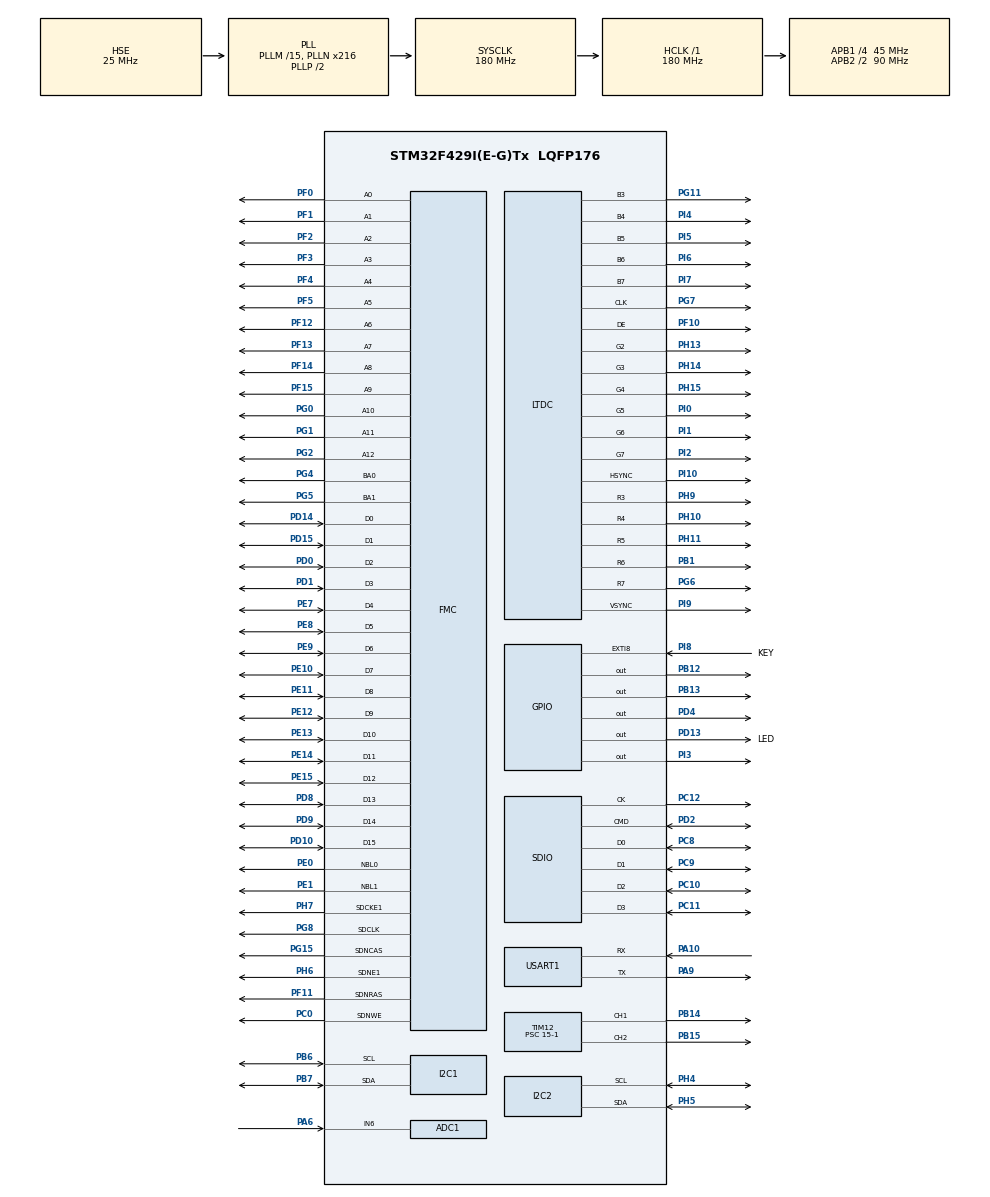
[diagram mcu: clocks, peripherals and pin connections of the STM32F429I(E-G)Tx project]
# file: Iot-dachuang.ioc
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ADC1.Channel-1\#ChannelRegularConversion=ADC_CHANNEL_6
ADC1.DMAContinuousRequests=ENABLE
ADC1.ExternalTrigConv=ADC_EXTERNALTRIGCONV_T3_TRGO
ADC1.NbrOfConversionFlag=1
ADC1.Rank-1\#ChannelRegularConversion=1
ADC1.SamplingTime-1\#ChannelRegularConversion=ADC_SAMPLETIME_3CYCLES
ADC1.master=1
DMA2D.ColorMode=DMA2D_OUTPUT_RGB565
DMA2D.Mode=DMA2D_M2M
Dma.ADC1.2.Direction=DMA_PERIPH_TO_MEMORY
Dma.ADC1.2.FIFOMode=DMA_FIFOMODE_DISABLE
Dma.ADC1.2.Instance=DMA2_Stream0
Dma.ADC1.2.MemDataAlignment=DMA_MDATAALIGN_HALFWORD
Dma.ADC1.2.MemInc=DMA_MINC_ENABLE
Dma.ADC1.2.Mode=DMA_NORMAL
Dma.ADC1.2.PeriphDataAlignment=DMA_PDATAALIGN_HALFWORD
Dma.ADC1.2.PeriphInc=DMA_PINC_DISABLE
Dma.ADC1.2.Priority=DMA_PRIORITY_LOW
Dma.Request0=SDIO_RX
Dma.Request1=SDIO_TX
Dma.Request2=ADC1
Dma.SDIO_RX.0.Direction=DMA_PERIPH_TO_MEMORY
Dma.SDIO_RX.0.FIFOMode=DMA_FIFOMODE_ENABLE
Dma.SDIO_RX.0.FIFOThreshold=DMA_FIFO_THRESHOLD_FULL
Dma.SDIO_RX.0.Instance=DMA2_Stream3
Dma.SDIO_RX.0.MemBurst=DMA_MBURST_INC4
Dma.SDIO_RX.0.MemDataAlignment=DMA_MDATAALIGN_WORD
Dma.SDIO_RX.0.MemInc=DMA_MINC_ENABLE
Dma.SDIO_RX.0.Mode=DMA_PFCTRL
Dma.SDIO_RX.0.PeriphBurst=DMA_PBURST_INC4
Dma.SDIO_RX.0.PeriphDataAlignment=DMA_PDATAALIGN_WORD
Dma.SDIO_RX.0.PeriphInc=DMA_PINC_DISABLE
Dma.SDIO_RX.0.Priority=DMA_PRIORITY_LOW
Dma.SDIO_TX.1.Direction=DMA_MEMORY_TO_PERIPH
Dma.SDIO_TX.1.FIFOMode=DMA_FIFOMODE_ENABLE
Dma.SDIO_TX.1.FIFOThreshold=DMA_FIFO_THRESHOLD_FULL
Dma.SDIO_TX.1.Instance=DMA2_Stream6
Dma.SDIO_TX.1.MemBurst=DMA_MBURST_INC4
Dma.SDIO_TX.1.MemDataAlignment=DMA_MDATAALIGN_WORD
Dma.SDIO_TX.1.MemInc=DMA_MINC_ENABLE
Dma.SDIO_TX.1.Mode=DMA_PFCTRL
Dma.SDIO_TX.1.PeriphBurst=DMA_PBURST_INC4
Dma.SDIO_TX.1.PeriphDataAlignment=DMA_PDATAALIGN_WORD
Dma.SDIO_TX.1.PeriphInc=DMA_PINC_DISABLE
Dma.SDIO_TX.1.Priority=DMA_PRIORITY_LOW
FATFS._CODE_PAGE=936
FATFS._USE_LFN=2
FATFS._USE_MUTEX=1
FMC.CASLatency2=FMC_SDRAM_CAS_LATENCY_3
FMC.ColumnBitsNumber2=FMC_SDRAM_COLUMN_BITS_NUM_9
FMC.ExitSelfRefreshDelay2=7
FMC.LoadToActiveDelay2=2
FMC.RCDDelay2=2
FMC.RPDelay2=2
FMC.ReadBurst2=FMC_SDRAM_RBURST_ENABLE
FMC.ReadPipeDelay2=FMC_SDRAM_RPIPE_DELAY_1
FMC.RowCycleDelay2=7
FMC.SDClockPeriod2=FMC_SDRAM_CLOCK_PERIOD_2
FMC.SelfRefreshTime2=4
FMC.WriteRecoveryTime2=3
FREERTOS.Tasks01=defaultTask,0,512,StartDefaultTask,Default,NULL,Dynamic,NULL,NULL;GUI,-3,512,GUItask,Default,NULL,Dynamic,NULL,NULL;Measure,-3,512,Measuretask,Default,NULL,Dynamic,NULL,NULL;Control,-3,128,Contorl,Default,NULL,Dynamic,NULL,NULL
FREERTOS.configENABLE_FPU=1
FREERTOS.configUSE_NEWLIB_REENTRANT=1
LTDC.ActiveH=272
LTDC.ActiveW=480
LTDC.Alpha_L0=255
LTDC.BlendingFactor1_L0=LTDC_BLENDING_FACTOR1_CA
LTDC.BlendingFactor1_L1=LTDC_BLENDING_FACTOR1_PAxCA
LTDC.BlendingFactor2_L0=LTDC_BLENDING_FACTOR2_CA
LTDC.BlendingFactor2_L1=LTDC_BLENDING_FACTOR2_PAxCA
LTDC.FBStartAdress_L0=0xD0000000
LTDC.FBStartAdress_L1=0xDD000000
LTDC.HBP=43
LTDC.HFP=8
LTDC.HSync=1
LTDC.ImageHeight_L0=272
LTDC.ImageHeight_L1=272
LTDC.ImageWidth_L0=480
LTDC.ImageWidth_L1=480
LTDC.Layers=0
LTDC.PixelFormat_L0=LTDC_PIXEL_FORMAT_RGB565
LTDC.VBP=12
LTDC.VFP=8
LTDC.VSync=1
LTDC.WindowX1_L0=480
LTDC.WindowX1_L1=480
LTDC.WindowY1_L0=272
LTDC.WindowY1_L1=272
Mcu.Family=STM32F4
Mcu.Name=STM32F429I(E-G)Tx
Mcu.Package=LQFP176
NVIC.DMA2D_IRQn=true\:5\:0\:false\:false\:true\:true\:true\:true\:true
NVIC.DMA2_Stream3_IRQn=true\:5\:0\:false\:false\:true\:true\:true\:true\:true
NVIC.DMA2_Stream6_IRQn=true\:5\:0\:false\:false\:true\:true\:true\:true\:true
NVIC.EXTI9_5_IRQn=true\:5\:0\:false\:false\:true\:true\:true\:true\:true
NVIC.LTDC_IRQn=true\:5\:0\:false\:false\:true\:true\:true\:true\:true
NVIC.PriorityGroup=NVIC_PRIORITYGROUP_4
NVIC.SDIO_IRQn=true\:5\:0\:false\:false\:true\:true\:true\:true\:true
NVIC.TIM1_UP_TIM10_IRQn=true\:5\:0\:false\:false\:true\:false\:false\:true\:true
NVIC.TimeBase=TIM1_UP_TIM10_IRQn
NVIC.TimeBaseIP=TIM1
NVIC.USART1_IRQn=true\:5\:0\:false\:false\:true\:true\:true\:true\:true
PA10.Mode=Asynchronous
PA10.Signal=USART1_RX
PA13.Mode=Serial_Wire
PA13.Signal=SYS_JTMS-SWDIO
PA14.Mode=Serial_Wire
PA14.Signal=SYS_JTCK-SWCLK
PA6.Signal=ADCx_IN6
PA9.Mode=Asynchronous
PA9.Signal=USART1_TX
PB1.GPIO_PuPd=GPIO_NOPULL
PB1.GPIO_Speed=GPIO_SPEED_FREQ_LOW
PB1.Mode=RGB565
PB1.Signal=LTDC_R6
PB12.GPIO_PuPd=GPIO_PULLUP
PB12.PinState=GPIO_PIN_SET
PB12.Signal=GPIO_Output
PB13.GPIO_PuPd=GPIO_PULLUP
PB13.PinState=GPIO_PIN_SET
PB13.Signal=GPIO_Output
PB14.GPIO_PuPd=GPIO_NOPULL
PB14.GPIO_Speed=GPIO_SPEED_FREQ_LOW
PB14.Signal=S_TIM12_CH1
PB15.Signal=S_TIM12_CH2
PB6.Mode=I2C
PB6.Signal=I2C1_SCL
PB7.Mode=I2C
PB7.Signal=I2C1_SDA
PC0.Signal=FMC_SDNWE
PC10.GPIO_PuPd=GPIO_PULLUP
PC10.Mode=SD_4_bits_Wide_bus
PC10.Signal=SDIO_D2
PC11.GPIO_PuPd=GPIO_PULLUP
PC11.Mode=SD_4_bits_Wide_bus
PC11.Signal=SDIO_D3
PC12.GPIO_PuPd=GPIO_PULLUP
PC12.Mode=SD_4_bits_Wide_bus
PC12.Signal=SDIO_CK
PC8.GPIO_PuPd=GPIO_PULLUP
PC8.Mode=SD_4_bits_Wide_bus
PC8.Signal=SDIO_D0
PC9.GPIO_PuPd=GPIO_PULLUP
PC9.Mode=SD_4_bits_Wide_bus
PC9.Signal=SDIO_D1
PD0.Signal=FMC_D2_DA2
PD1.Signal=FMC_D3_DA3
PD10.Signal=FMC_D15_DA15
PD13.GPIO_Label=LED
PD13.GPIO_PuPd=GPIO_PULLUP
PD13.PinState=GPIO_PIN_SET
PD13.Signal=GPIO_Output
PD14.Signal=FMC_D0_DA0
PD15.Signal=FMC_D1_DA1
PD2.GPIO_PuPd=GPIO_PULLUP
PD2.Mode=SD_4_bits_Wide_bus
PD2.Signal=SDIO_CMD
PD4.Signal=GPIO_Output
PD8.Signal=FMC_D13_DA13
PD9.Signal=FMC_D14_DA14
PE0.Signal=FMC_NBL0
PE1.Signal=FMC_NBL1
PE10.Signal=FMC_D7_DA7
PE11.Signal=FMC_D8_DA8
PE12.Signal=FMC_D9_DA9
PE13.Signal=FMC_D10_DA10
PE14.Signal=FMC_D11_DA11
PE15.Signal=FMC_D12_DA12
PE7.Signal=FMC_D4_DA4
PE8.Signal=FMC_D5_DA5
PE9.Signal=FMC_D6_DA6
PF0.Signal=FMC_A0
PF1.Signal=FMC_A1
PF10.GPIO_PuPd=GPIO_NOPULL
PF10.GPIO_Speed=GPIO_SPEED_FREQ_LOW
PF10.Mode=RGB565
PF10.Signal=LTDC_DE
PF11.Signal=FMC_SDNRAS
PF12.Signal=FMC_A6
PF13.Signal=FMC_A7
PF14.Signal=FMC_A8
PF15.Signal=FMC_A9
PF2.Signal=FMC_A2
PF3.Signal=FMC_A3
PF4.Signal=FMC_A4
PF5.Signal=FMC_A5
PG0.Signal=FMC_A10
PG1.Signal=FMC_A11
PG11.GPIO_PuPd=GPIO_NOPULL
PG11.GPIO_Speed=GPIO_SPEED_FREQ_LOW
PG11.Mode=RGB565
PG11.Signal=LTDC_B3
PG15.Signal=FMC_SDNCAS
PG2.Signal=FMC_A12
PG4.Signal=FMC_A14_BA0
PG5.Signal=FMC_A15_BA1
PG6.GPIO_PuPd=GPIO_NOPULL
PG6.GPIO_Speed=GPIO_SPEED_FREQ_LOW
PG6.Mode=RGB565
PG6.Signal=LTDC_R7
PG7.GPIO_PuPd=GPIO_NOPULL
PG7.GPIO_Speed=GPIO_SPEED_FREQ_LOW
PG7.Mode=RGB565
PG7.Signal=LTDC_CLK
PG8.Signal=FMC_SDCLK
PH0/OSC_IN.Mode=HSE-External-Oscillator
PH0/OSC_IN.Signal=RCC_OSC_IN
PH1/OSC_OUT.Mode=HSE-External-Oscillator
PH1/OSC_OUT.Signal=RCC_OSC_OUT
PH10.GPIO_PuPd=GPIO_NOPULL
PH10.GPIO_Speed=GPIO_SPEED_FREQ_LOW
PH10.Mode=RGB565
PH10.Signal=LTDC_R4
PH11.GPIO_PuPd=GPIO_NOPULL
PH11.GPIO_Speed=GPIO_SPEED_FREQ_LOW
PH11.Mode=RGB565
PH11.Signal=LTDC_R5
PH13.GPIO_PuPd=GPIO_NOPULL
PH13.GPIO_Speed=GPIO_SPEED_FREQ_LOW
PH13.Mode=RGB565
PH13.Signal=LTDC_G2
PH14.GPIO_PuPd=GPIO_NOPULL
PH14.GPIO_Speed=GPIO_SPEED_FREQ_LOW
PH14.Mode=RGB565
PH14.Signal=LTDC_G3
PH15.GPIO_PuPd=GPIO_NOPULL
PH15.GPIO_Speed=GPIO_SPEED_FREQ_LOW
PH15.Mode=RGB565
PH15.Signal=LTDC_G4
PH4.Mode=I2C
PH4.Signal=I2C2_SCL
PH5.Mode=I2C
PH5.Signal=I2C2_SDA
PH6.Mode=SdramChipSelect2_2
PH6.Signal=FMC_SDNE1
PH7.Mode=SdramChipSelect2_2
PH7.Signal=FMC_SDCKE1
PH9.GPIO_PuPd=GPIO_NOPULL
PH9.GPIO_Speed=GPIO_SPEED_FREQ_LOW
PH9.Mode=RGB565
PH9.Signal=LTDC_R3
PI0.GPIO_PuPd=GPIO_NOPULL
PI0.GPIO_Speed=GPIO_SPEED_FREQ_LOW
PI0.Mode=RGB565
PI0.Signal=LTDC_G5
PI1.GPIO_PuPd=GPIO_NOPULL
PI1.GPIO_Speed=GPIO_SPEED_FREQ_LOW
PI1.Mode=RGB565
PI1.Signal=LTDC_G6
PI10.GPIO_PuPd=GPIO_NOPULL
PI10.GPIO_Speed=GPIO_SPEED_FREQ_LOW
PI10.Mode=RGB565
PI10.Signal=LTDC_HSYNC
PI2.GPIO_PuPd=GPIO_NOPULL
PI2.GPIO_Speed=GPIO_SPEED_FREQ_LOW
PI2.Mode=RGB565
PI2.Signal=LTDC_G7
PI3.GPIO_PuPd=GPIO_NOPULL
PI3.PinState=GPIO_PIN_RESET
PI3.Signal=GPIO_Output
PI4.GPIO_PuPd=GPIO_NOPULL
PI4.GPIO_Speed=GPIO_SPEED_FREQ_LOW
PI4.Mode=RGB565
PI4.Signal=LTDC_B4
PI5.GPIO_PuPd=GPIO_NOPULL
PI5.GPIO_Speed=GPIO_SPEED_FREQ_LOW
PI5.Mode=RGB565
PI5.Signal=LTDC_B5
PI6.GPIO_PuPd=GPIO_NOPULL
PI6.GPIO_Speed=GPIO_SPEED_FREQ_LOW
PI6.Mode=RGB565
PI6.Signal=LTDC_B6
PI7.GPIO_PuPd=GPIO_NOPULL
PI7.GPIO_Speed=GPIO_SPEED_FREQ_LOW
PI7.Mode=RGB565
PI7.Signal=LTDC_B7
PI8.GPIO_Label=KEY
PI8.GPIO_PuPd=GPIO_PULLUP
PI8.Signal=GPXTI8
PI9.GPIO_PuPd=GPIO_NOPULL
PI9.GPIO_Speed=GPIO_SPEED_FREQ_LOW
PI9.Mode=RGB565
PI9.Signal=LTDC_VSYNC
ProjectManager.HeapSize=0x2000
ProjectManager.StackSize=0x4000
ProjectManager.TargetToolchain=STM32CubeIDE
RCC.48MHZClocksFreq_Value=40000000
RCC.AHBFreq_Value=180000000
RCC.APB1CLKDivider=RCC_HCLK_DIV4
RCC.APB1Freq_Value=45000000
RCC.APB1TimFreq_Value=90000000
RCC.APB2CLKDivider=RCC_HCLK_DIV2
RCC.APB2Freq_Value=90000000
RCC.APB2TimFreq_Value=180000000
RCC.CortexFreq_Value=180000000
RCC.HCLKFreq_Value=180000000
RCC.HSE_VALUE=25000000
RCC.HSI_VALUE=16000000
RCC.LSE_VALUE=32768
RCC.PLLM=15
RCC.PLLN=216
RCC.PLLQ=9
RCC.PLLSAIDivR=RCC_PLLSAIDIVR_4
RCC.PLLSAIN=60
RCC.PLLSourceVirtual=RCC_PLLSOURCE_HSE
RCC.SYSCLKFreq_VALUE=180000000
RCC.SYSCLKSource=RCC_SYSCLKSOURCE_PLLCLK
RCC.VCOOutputFreq_Value=360000000
SDIO.ClockDiv=2
SH.ADCx_IN6.0=ADC1_IN6,IN6
SH.FMC_A0.0=FMC_A0,13b-sda2
SH.FMC_A1.0=FMC_A1,13b-sda2
SH.FMC_A10.0=FMC_A10,13b-sda2
SH.FMC_A11.0=FMC_A11,13b-sda2
SH.FMC_A12.0=FMC_A12,13b-sda2
SH.FMC_A14_BA0.0=FMC_BA0,FourSdramBanks2
SH.FMC_A15_BA1.0=FMC_BA1,FourSdramBanks2
SH.FMC_A2.0=FMC_A2,13b-sda2
SH.FMC_A3.0=FMC_A3,13b-sda2
SH.FMC_A4.0=FMC_A4,13b-sda2
SH.FMC_A5.0=FMC_A5,13b-sda2
SH.FMC_A6.0=FMC_A6,13b-sda2
SH.FMC_A7.0=FMC_A7,13b-sda2
SH.FMC_A8.0=FMC_A8,13b-sda2
SH.FMC_A9.0=FMC_A9,13b-sda2
SH.FMC_D0_DA0.0=FMC_D0,sd-16b-d2
SH.FMC_D10_DA10.0=FMC_D10,sd-16b-d2
SH.FMC_D11_DA11.0=FMC_D11,sd-16b-d2
SH.FMC_D12_DA12.0=FMC_D12,sd-16b-d2
SH.FMC_D13_DA13.0=FMC_D13,sd-16b-d2
SH.FMC_D14_DA14.0=FMC_D14,sd-16b-d2
SH.FMC_D15_DA15.0=FMC_D15,sd-16b-d2
SH.FMC_D1_DA1.0=FMC_D1,sd-16b-d2
SH.FMC_D2_DA2.0=FMC_D2,sd-16b-d2
SH.FMC_D3_DA3.0=FMC_D3,sd-16b-d2
SH.FMC_D4_DA4.0=FMC_D4,sd-16b-d2
SH.FMC_D5_DA5.0=FMC_D5,sd-16b-d2
SH.FMC_D6_DA6.0=FMC_D6,sd-16b-d2
SH.FMC_D7_DA7.0=FMC_D7,sd-16b-d2
SH.FMC_D8_DA8.0=FMC_D8,sd-16b-d2
SH.FMC_D9_DA9.0=FMC_D9,sd-16b-d2
SH.FMC_NBL0.0=FMC_NBL0,Sd2ByteEnable2
SH.FMC_NBL1.0=FMC_NBL1,Sd2ByteEnable2
SH.FMC_SDCLK.0=FMC_SDCLK,13b-sda2
SH.FMC_SDNCAS.0=FMC_SDNCAS,13b-sda2
SH.FMC_SDNRAS.0=FMC_SDNRAS,13b-sda2
SH.FMC_SDNWE.0=FMC_SDNWE,13b-sda2
SH.S_TIM12_CH1.0=TIM12_CH1,PWM Generation1 CH1
SH.S_TIM12_CH2.0=TIM12_CH2,PWM Generation2 CH2
STMicroelectronics.X-CUBE-TOUCHGFX.4.18.1.ApplicationCcGraphicsJjApplication=TouchGFXOoGenerator
STMicroelectronics.X-CUBE-TOUCHGFX.4.18.1.tgfx_address1=0xD0000000
STMicroelectronics.X-CUBE-TOUCHGFX.4.18.1.tgfx_address2=0xD0080000
STMicroelectronics.X-CUBE-TOUCHGFX.4.18.1.tgfx_buffering_strategy=Double
STMicroelectronics.X-CUBE-TOUCHGFX.4.18.1.tgfx_custom_height=272
STMicroelectronics.X-CUBE-TOUCHGFX.4.18.1.tgfx_display_interface=disp_ltdc
STMicroelectronics.X-CUBE-TOUCHGFX.4.18.1.tgfx_hardware_accelerator=dma_2d
STMicroelectronics.X-CUBE-TOUCHGFX.4.18.1.tgfx_location=By Address
STMicroelectronics.X-CUBE-TOUCHGFX.4.18.1.tgfx_vsync=vsync_ltdc
STMicroelectronics.X-CUBE-TOUCHGFX.4.18.1_IsPackSelfContextualization=true
TIM12.AutoReloadPreload=TIM_AUTORELOAD_PRELOAD_ENABLE
TIM12.Channel-PWM\ Generation1\ CH1=TIM_CHANNEL_1
TIM12.Channel-PWM\ Generation2\ CH2=TIM_CHANNEL_2
TIM12.ClockDivision=TIM_CLOCKDIVISION_DIV1
TIM12.OCPolarity_1=TIM_OCPOLARITY_HIGH
TIM12.OCPolarity_2=TIM_OCPOLARITY_HIGH
TIM12.Period=20000-1
TIM12.Prescaler=15-1
TIM12.Pulse-PWM\ Generation1\ CH1=15000
TIM12.Pulse-PWM\ Generation2\ CH2=15000
TIM3.AutoReloadPreload=TIM_AUTORELOAD_PRELOAD_ENABLE
TIM3.Prescaler=90
TIM3.TIM_MasterOutputTrigger=TIM_TRGO_UPDATE
USART1.VirtualMode=VM_ASYNC
VP_CRC_VS_CRC.Mode=CRC_Activate
VP_DMA2D_VS_DMA2D.Mode=DMA2D_Activate
VP_FATFS_VS_SDIO.Mode=SDIO
VP_FREERTOS_VS_CMSIS_V1.Mode=CMSIS_V1
VP_STMicroelectronics.X-CUBE-TOUCHGFX_VS_GraphicsJjApplication_4.18.1.Mode=GraphicsJjApplication
VP_SYS_VS_tim1.Mode=TIM1
VP_TIM12_VS_ClockSourceINT.Mode=Internal
VP_TIM3_VS_ClockSourceINT.Mode=Internal
board=custom

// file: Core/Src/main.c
/* USER CODE BEGIN Header */
/**
  ******************************************************************************
  * @file           : main.c
  * @brief          : Main program body
  ******************************************************************************
  * @attention
  *
  * Copyright (c) 2022 STMicroelectronics.
  * All rights reserved.
  *
  * This software is licensed under terms that can be found in the LICENSE file
  * in the root directory of this software component.
  * If no LICENSE file comes with this software, it is provided AS-IS.
  *
  ******************************************************************************
  */
/* USER CODE END Header */
#include "main.h"
#include "cmsis_os.h"
#include "adc.h"
#include "crc.h"
#include "dma.h"
#include "dma2d.h"
#include "fatfs.h"
#include "i2c.h"
#include "ltdc.h"
#include "sdio.h"
#include "tim.h"
#include "usart.h"
#include "gpio.h"
#include "fmc.h"
#include "app_touchgfx.h"

/* USER CODE BEGIN Includes */
#include "devices.h"
#include "stdlib.h"

/* USER CODE END Includes */

/* USER CODE BEGIN PV */
char httprxbuffer[356]={};
char org[4];
uint16_t cmd;
uint16_t cpr;
/* USER CODE END PV */

void SystemClock_Config(void);
void MX_FREERTOS_Init(void);

int main(void)
{

  /* MCU Configuration--------------------------------------------------------*/

  /* Reset of all peripherals, Initializes the Flash interface and the Systick. */
  HAL_Init();

  /* Configure the system clock */
  SystemClock_Config();

  /* Initialize all configured peripherals */
  MX_GPIO_Init();
  MX_USART1_UART_Init();
  MX_FMC_Init();
  MX_LTDC_Init();
  MX_DMA2D_Init();
  MX_CRC_Init();
  MX_I2C1_Init();
  MX_DMA_Init();
  MX_SDIO_SD_Init();
  MX_FATFS_Init();
  MX_ADC1_Init();
  MX_TIM3_Init();
  MX_TIM12_Init();
  MX_I2C2_Init();
  MX_TouchGFX_Init();
  /* USER CODE BEGIN 2 */

  HAL_UART_Receive_IT(&huart1,(uint8_t*)httprxbuffer,356);
  HAL_GPIO_WritePin(GPIOD, GPIO_PIN_4, 0);
  HAL_GPIO_WritePin(GPIOI, GPIO_PIN_3, 0);
  HAL_GPIO_WritePin(GPIOB, GPIO_PIN_12, 1);
  HAL_GPIO_WritePin(GPIOB, GPIO_PIN_13, 1);
  HAL_TIM_Base_Start(&htim3);
  HAL_TIM_PWM_Start(&htim12, TIM_CHANNEL_1);
  HAL_TIM_PWM_Start(&htim12, TIM_CHANNEL_2);

  /* USER CODE END 2 */

  /* Call init function for freertos objects (in freertos.c) */
  MX_FREERTOS_Init();

  /* Start scheduler */
  osKernelStart();

  /* We should never get here as control is now taken by the scheduler */
  /* Infinite loop */
  while (1)
  {

  }
}

void SystemClock_Config(void)
{
  RCC_OscInitTypeDef RCC_OscInitStruct = {0};
  RCC_ClkInitTypeDef RCC_ClkInitStruct = {0};

  /** Configure the main internal regulator output voltage
  */
  __HAL_RCC_PWR_CLK_ENABLE();
  __HAL_PWR_VOLTAGESCALING_CONFIG(PWR_REGULATOR_VOLTAGE_SCALE1);

  /** Initializes the RCC Oscillators according to the specified parameters
  * in the RCC_OscInitTypeDef structure.
  */
  RCC_OscInitStruct.OscillatorType = RCC_OSCILLATORTYPE_HSE;
  RCC_OscInitStruct.HSEState = RCC_HSE_ON;
  RCC_OscInitStruct.PLL.PLLState = RCC_PLL_ON;
  RCC_OscInitStruct.PLL.PLLSource = RCC_PLLSOURCE_HSE;
  RCC_OscInitStruct.PLL.PLLM = 15;
  RCC_OscInitStruct.PLL.PLLN = 216;
  RCC_OscInitStruct.PLL.PLLP = RCC_PLLP_DIV2;
  RCC_OscInitStruct.PLL.PLLQ = 9;
  if (HAL_RCC_OscConfig(&RCC_OscInitStruct) != HAL_OK)
  {
    Error_Handler();
  }

  /** Activate the Over-Drive mode
  */
  if (HAL_PWREx_EnableOverDrive() != HAL_OK)
  {
    Error_Handler();
  }

  /** Initializes the CPU, AHB and APB buses clocks
  */
  RCC_ClkInitStruct.ClockType = RCC_CLOCKTYPE_HCLK|RCC_CLOCKTYPE_SYSCLK
                              |RCC_CLOCKTYPE_PCLK1|RCC_CLOCKTYPE_PCLK2;
  RCC_ClkInitStruct.SYSCLKSource = RCC_SYSCLKSOURCE_PLLCLK;
  RCC_ClkInitStruct.AHBCLKDivider = RCC_SYSCLK_DIV1;
  RCC_ClkInitStruct.APB1CLKDivider = RCC_HCLK_DIV4;
  RCC_ClkInitStruct.APB2CLKDivider = RCC_HCLK_DIV2;

  if (HAL_RCC_ClockConfig(&RCC_ClkInitStruct, FLASH_LATENCY_5) != HAL_OK)
  {
    Error_Handler();
  }
}

/* USER CODE BEGIN 4 */

void HAL_UART_RxCpltCallback(UART_HandleTypeDef *huart){
	if(huart->Instance == USART1){
		HAL_GPIO_TogglePin(GPIOD, GPIO_PIN_4);
/*		if (httprxbuffer[9]=='2') {*/

			org[0]=httprxbuffer[277];
			org[1]=httprxbuffer[285];
			org[2]=httprxbuffer[297];
			org[3]=httprxbuffer[308];
			cmd=atoi(org);

//				HAL_GPIO_WritePin(GPIOD, GPIO_PIN_4, 0);
				room.heater = cmd/1000%10;
				room.fan1 = room.fan2 = cmd/100%10;
				room.curtain = cmd/10%10;
				room.window = cmd%10;
/*		}*/
		HAL_UART_Receive_IT(&huart1,(uint8_t*)httprxbuffer,356);
	}
}
/* USER CODE END 4 */

void HAL_TIM_PeriodElapsedCallback(TIM_HandleTypeDef *htim)
{
  if (htim->Instance == TIM1) {
    HAL_IncTick();
  }
}

void Error_Handler(void)
{
  __disable_irq();
  while (1)
  {
  }
}

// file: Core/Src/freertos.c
/* USER CODE BEGIN Header */
/**
  ******************************************************************************
  * File Name          : freertos.c
  * Description        : Code for freertos applications
  ******************************************************************************
  * @attention
  *
  * Copyright (c) 2022 STMicroelectronics.
  * All rights reserved.
  *
  * This software is licensed under terms that can be found in the LICENSE file
  * in the root directory of this software component.
  * If no LICENSE file comes with this software, it is provided AS-IS.
  *
  ******************************************************************************
  */
/* USER CODE END Header */

#include "FreeRTOS.h"
#include "task.h"
#include "main.h"
#include "cmsis_os.h"

/* USER CODE BEGIN Includes */
#include "fatfs.h"
#include "stdio.h"
#include "stm32f4xx.h"
#include "i2c.h"
#include "adc.h"
#include "tim.h"
#include "usart.h"
#include "devices.h"
#include "math.h"
#include "sht31.h"
#include "bh1750.h"
#include "sgp30.h"
/* USER CODE END Includes */

/* USER CODE BEGIN Variables */
uint32_t NH3[1];
__IO float temperature = 20.32 , humidity = 56.93, lux, nh3;
__IO uint16_t co2,TVOC;

uint8_t count = 50;
uint8_t count1 = 50;
uint8_t count2 = 50;

uint8_t Addtion = 0;
uint8_t Addtion1 = 0;
uint8_t Addtion2 = 0;

uint8_t Deletion = 0;
uint8_t Deletion1 = 0;
uint8_t Deletion2 = 0;

char httpbody[600];

uint8_t homestate = 0;
int wrflag = 0;
sht3x_handle_t shthandle = {
	  	              .i2c_handle = &hi2c1,
	  	              .device_address = SHT3X_I2C_DEVICE_ADDRESS_ADDR_PIN_LOW
	  	      };

/* USER CODE END Variables */
osThreadId defaultTaskHandle;
osThreadId GUIHandle;
osThreadId MeasureHandle;
osThreadId ControlHandle;

void StartDefaultTask(void const * argument);
void GUItask(void const * argument);
void Measuretask(void const * argument);
void Contorl(void const * argument);

void MX_FREERTOS_Init(void); /* (MISRA C 2004 rule 8.1) */

/* GetIdleTaskMemory prototype (linked to static allocation support) */
void vApplicationGetIdleTaskMemory( StaticTask_t **ppxIdleTaskTCBBuffer, StackType_t **ppxIdleTaskStackBuffer, uint32_t *pulIdleTaskStackSize );

/* USER CODE BEGIN GET_IDLE_TASK_MEMORY */
static StaticTask_t xIdleTaskTCBBuffer;
static StackType_t xIdleStack[configMINIMAL_STACK_SIZE];

void vApplicationGetIdleTaskMemory( StaticTask_t **ppxIdleTaskTCBBuffer, StackType_t **ppxIdleTaskStackBuffer, uint32_t *pulIdleTaskStackSize )
{
  *ppxIdleTaskTCBBuffer = &xIdleTaskTCBBuffer;
  *ppxIdleTaskStackBuffer = &xIdleStack[0];
  *pulIdleTaskStackSize = configMINIMAL_STACK_SIZE;
  /* place for user code */
}
/* USER CODE END GET_IDLE_TASK_MEMORY */

void MX_FREERTOS_Init(void) {
  /* USER CODE BEGIN Init */
	HAL_ADC_Start_DMA(&hadc1, NH3, 1);
	sht3x_init(&shthandle);
	BH1750_Init(&hi2c2);
	BH1750_SetMode(CONTINUOUS_LOW_RES_MODE);
	sgp30_init();
  /* USER CODE END Init */

  /* Create the thread(s) */
  /* definition and creation of defaultTask */
  osThreadDef(defaultTask, StartDefaultTask, osPriorityNormal, 0, 512);
  defaultTaskHandle = osThreadCreate(osThread(defaultTask), NULL);

  /* definition and creation of GUI */
  osThreadDef(GUI, GUItask, osPriorityIdle, 0, 512);
  GUIHandle = osThreadCreate(osThread(GUI), NULL);

  /* definition and creation of Measure */
  osThreadDef(Measure, Measuretask, osPriorityIdle, 0, 512);
  MeasureHandle = osThreadCreate(osThread(Measure), NULL);

  /* definition and creation of Control */
  osThreadDef(Control, Contorl, osPriorityIdle, 0, 128);
  ControlHandle = osThreadCreate(osThread(Control), NULL);

}

void StartDefaultTask(void const * argument)
{
  /* USER CODE BEGIN StartDefaultTask */
	char wrbuf[20];
	retSD = f_mount(&SDFatFS, SDPath, 1);
	retSD = f_open(&SDFile,"0:\\out.txt", FA_CREATE_NEW | FA_WRITE |FA_READ);
	retSD = f_close(&SDFile);

	/* Infinite loop */
  for(;;)
  {
	if(wrflag == 1){
		retSD = f_open(&SDFile,"0:\\out.txt", FA_OPEN_EXISTING | FA_WRITE |FA_READ);
		retSD=f_lseek(&SDFile,f_size(&SDFile));
		sprintf(wrbuf,"lux:%.1f\r\n",lux);
		f_printf(&SDFile,wrbuf);
		sprintf(wrbuf,"humi:%.1f%\r\n",humidity);
		f_printf(&SDFile,wrbuf);
		sprintf(wrbuf,"temp:%.1f\r\n",temperature);
		f_printf(&SDFile,wrbuf);
		sprintf(wrbuf,"CO2:%f%\r\n",co2);
		f_printf(&SDFile,wrbuf);
		f_printf(&SDFile,"\r\n");
		retSD = f_close(&SDFile);
		wrflag = 0;
	}

    osDelay(1);
  }
  /* USER CODE END StartDefaultTask */
}

void GUItask(void const * argument)
{
  /* USER CODE BEGIN GUItask */

  /* Infinite loop */
  for(;;)
  {
	MX_TouchGFX_Process();
    osDelay(1);
  }
  /* USER CODE END GUItask */
}

void Measuretask(void const * argument)
{
  /* USER CODE BEGIN Measuretask */
  /* Infinite loop */
  for(;;)
  {
	  sht3x_read_temperature_and_humidity(&shthandle, &temperature, &humidity);
	  sgp30_read(&co2, &TVOC);
	  BH1750_ReadLight(&lux);
	  HAL_ADC_Start_DMA(&hadc1, (uint32_t*)NH3, 1);
	  nh3 = NH3[0];
	  nh3 = nh3* 3.3 / 4096;
	  nh3 = 410*nh3*nh3*nh3*nh3*nh3 - 2718*nh3*nh3*nh3*nh3 + 7015*nh3*nh3*nh3 - 8748*nh3*nh3  + 5271*nh3 - 1128;
	  vTaskDelay(2500);
	  sprintf(httpbody,"POST /postData HTTP/1.1\r\nUser-Agent: PostmanRuntime/7.28.2\r\nAccept: */*\r\nHost: 121.40.34.200:7890\r\nAccept-Encoding: gzip, deflate, br\r\nConnection: keep-alive\r\nContent-Type: application/x-www-form-urlencoded\r\nContent-Length: 235\r\n\r\ntemperature=%.2f&humidity=%.2f&light=%03d&coo_gas=%03d&amm_gas=%03d&pig_total=%2d&pig_add=%02d&pig_death=%02d&cow_total=%02d&cow_add=%02d&cow_death=%02d&sheep_total=%02d&sheep_add=%02d&sheep_death=%02d&Heater=%d&Fan=%d&Curtain=%d&Window=%d",
			  temperature,humidity,(uint16_t)lux,(uint16_t)co2,(uint16_t)nh3,count1,Addtion1,Deletion1,count2,Addtion2,Deletion2,count,Addtion,Deletion,room.heater,room.fan1,room.curtain,room.window);
	  HAL_UART_Transmit(&huart1, httpbody, 466, 1000);

	  osDelay(1);
  }
  /* USER CODE END Measuretask */
}

void Contorl(void const * argument)
{
  /* USER CODE BEGIN Contorl */
  /* Infinite loop */
  for(;;)
  {
	fanctrl(room);
	if(room.window)	{
		windowon(room);
	}else {
		windowoff(room);
		}
	if (room.curtain) {
		curtainup();
	}else {
		curtaindown();
		}
	if (room.heater) {
		heateron();
	}else {
			heateroff();
		}

    osDelay(1);
  }
  /* USER CODE END Contorl */
}
